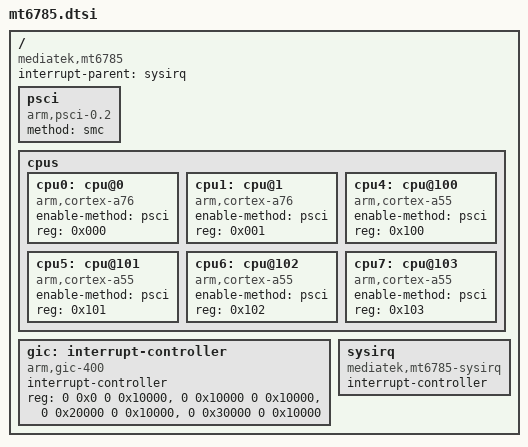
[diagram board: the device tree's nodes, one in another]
/*
 * Copyright (c) 2024 MediaTek Inc.
 * Author: Neko Kernel Project
 *
 * This program is free software; you can redistribute it and/or modify
 * it under the terms of the GNU General Public License version 2 as
 * published by the Free Software Foundation.
 *
 * This program is distributed in the hope that it will be useful,
 * but WITHOUT ANY WARRANTY; without even the implied warranty of
 * MERCHANTABILITY or FITNESS FOR A PARTICULAR PURPOSE.  See the
 * GNU General Public License for more details.
 */

#include <dt-bindings/interrupt-controller/irq.h>
#include <dt-bindings/interrupt-controller/arm-gic.h>

/ {
	compatible = "mediatek,mt6785", "mediatek,mt6785";
	interrupt-parent = <&sysirq>;
	#address-cells = <2>;
	#size-cells = <2>;

	psci {
		compatible = "arm,psci-0.2";
		method = "smc";
	};

	cpus {
		#address-cells = <1>;
		#size-cells = <0>;

		/* Performance cluster (Cortex-A76) */
		cpu0: cpu@0 {
			device_type = "cpu";
			compatible = "arm,cortex-a76";
			enable-method = "psci";
			reg = <0x000>;
		};

		cpu1: cpu@1 {
			device_type = "cpu";
			compatible = "arm,cortex-a76";
			enable-method = "psci";
			reg = <0x001>;
		};

		/* Efficiency cluster (Cortex-A55) */
		cpu4: cpu@100 {
			device_type = "cpu";
			compatible = "arm,cortex-a55";
			enable-method = "psci";
			reg = <0x100>;
		};

		cpu5: cpu@101 {
			device_type = "cpu";
			compatible = "arm,cortex-a55";
			enable-method = "psci";
			reg = <0x101>;
		};

		cpu6: cpu@102 {
			device_type = "cpu";
			compatible = "arm,cortex-a55";
			enable-method = "psci";
			reg = <0x102>;
		};

		cpu7: cpu@103 {
			device_type = "cpu";
			compatible = "arm,cortex-a55";
			enable-method = "psci";
			reg = <0x103>;
		};
	};

	gic: interrupt-controller {
		compatible = "arm,gic-400";
		#interrupt-cells = <3>;
		interrupt-controller;
		reg = <0 0x0 0 0x10000>,
		      <0 0x10000 0 0x10000>,
		      <0 0x20000 0 0x10000>,
		      <0 0x30000 0 0x10000>;
	};

	sysirq: sysirq {
		compatible = "mediatek,mt6785-sysirq";
		interrupt-controller;
		#interrupt-cells = <1>;
	};
};
